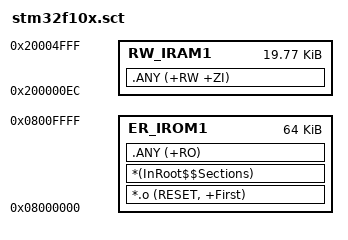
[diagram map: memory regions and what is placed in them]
; *************************************************************
; *** Scatter-Loading Description File generated by uVision ***
; *************************************************************

LR_IROM1 0x08000000 0x00010000  {    ; load region size_region
  ER_IROM1 0x08000000 0x00010000  {  ; load address = execution address
   *.o (RESET, +First)
   *(InRoot$$Sections)
   .ANY (+RO)
  }
  ;RW_IRAM1 0x20000000 0x00005000  {  ; RW data
  ; 59 vectors (16 core + 43 peripheral) * 4 bytes = 236 bytes to reserve (0xEC)
  ; 20KB - 0xEC = 0x5000 - 0xEC = 0x4F14 bytes after reserved area
  RW_IRAM1 0x200000EC 0x00004F14  {  ; RW data
   .ANY (+RW +ZI)
  }
}

